# SAM9X75D1GN2 device description
Architecture: ARM926EJ-S; Family: SAM9; Series: SAM9X7
Registers are 32-bit, read-write, reset 0x0 unless marked. A register's access mark holds for its fields unless they carry their own. Offsets are from the block's base; [hi:lo] are bit positions; lines under a group give offsets from that group; {n}, {i} and the like mark numbered series; 'fields as' and 'values as' point back to an identical list.

## PWM — Pulse Width Modulation Controller
Instances: PWM 0xF8034000
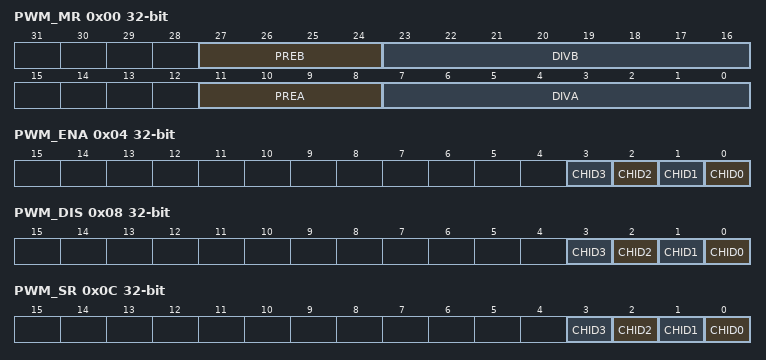
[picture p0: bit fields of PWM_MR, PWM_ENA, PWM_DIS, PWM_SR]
0x00 PWM_MR — PWM Mode Register
  [27:24] PREB — CLKB Source Clock Selection
    0=MCK (Peripheral clock); 1=MCKDIV2 (Peripheral clock divided by 2); 2=MCKDIV4 (Peripheral clock divided by 4); 3=MCKDIV8 (Peripheral clock divided by 8); 4=MCKDIV16 (Peripheral clock divided by 16); 5=MCKDIV32 (Peripheral clock divided by 32); 6=MCKDIV64 (Peripheral clock divided by 64); 7=MCKDIV128 (Peripheral clock divided by 128); 8=MCKDIV256 (Peripheral clock divided by 256); 9=MCKDIV512 (Peripheral clock divided by 512); 10=MCKDIV1024 (Peripheral clock divided by 1024)
  [23:16] DIVB — CLKB Divide Factor
    0=CLK_OFF (The CLKB internal source clock is turned off. The PWMx output is stuck when PWM_CMRx.CPRE=CLKB.); 1=CLK_DIV1 (CLKB is the clock selected by PREB.)
  [11:8] PREA — CLKA Source Clock Selection
    values as PREB
  [7:0] DIVA — CLKA Divide Factor
    0=CLK_OFF (The CLKA internal source clock is turned off. The PWMx output is stuck when PWM_CMRx.CPRE=CLKA.); 1=CLK_DIV1 (CLKA is the clock selected by PREA.)
0x04 PWM_ENA wo reset not defined — PWM Enable Register
  [all] fields
    0=No effect; 1=Enable PWM output for channel x
  [n] CHID{n} (n=0..3) — Channel ID
0x08 PWM_DIS wo reset not defined (atomic clear of PWM_SR) — PWM Disable Register
  [all] fields
    0=No effect; 1=Disable PWM output for channel x
  [n] CHID{n} (n=0..3) — Channel ID
0x0C PWM_SR ro — PWM Status Register
  [all] fields
    0=PWM output for channel x is disabled; 1=PWM output for channel x is enabled
  [n] CHID{n} (n=0..3) — Channel ID
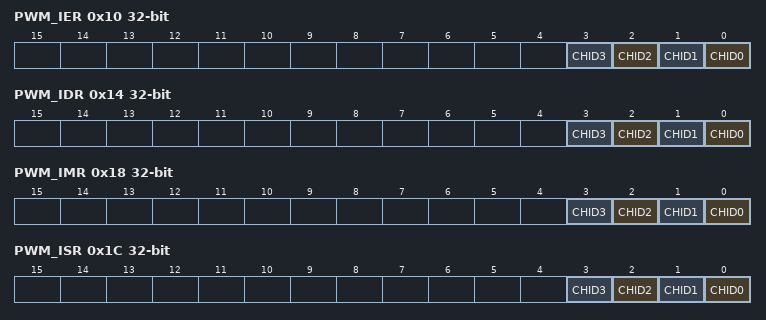
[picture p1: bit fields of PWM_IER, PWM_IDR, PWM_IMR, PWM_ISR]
0x10 PWM_IER wo reset not defined (atomic set of PWM_IMR) — PWM Interrupt Enable Register
  [all] fields
    0=No effect; 1=Enable interrupt for PWM channel x
  [n] CHID{n} (n=0..3) — Channel ID
0x14 PWM_IDR wo reset not defined (atomic clear of PWM_IMR) — PWM Interrupt Disable Register
  [all] fields
    0=No effect; 1=Disable interrupt for PWM channel x
  [n] CHID{n} (n=0..3) — Channel ID
0x18 PWM_IMR ro — PWM Interrupt Mask Register
  [all] fields
    0=Interrupt for PWM channel x is disabled; 1=Interrupt for PWM channel x is enabled
  [n] CHID{n} (n=0..3) — Channel ID
0x1C PWM_ISR ro — PWM Interrupt Status Register
  [all] fields
    0=No new channel period has been achieved since the last read of PWM_ISR; 1=At least one new channel period has been achieved since the last read of PWM_ISR
  [n] CHID{n} (n=0..3) — Channel ID
{0x200+0x20*i} PWM_CH_NUM[{i}] (i=0..3) group
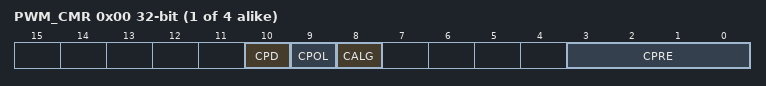
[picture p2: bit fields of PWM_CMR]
  0x00 PWM_CMR — PWM Channel Mode Register
    [10] CPD — Channel Update Period
      0=Writing to PWM_CUPDx will modify the duty cycle at the next period start event; 1=Writing to PWM_CUPDx will modify the period at the next period start event
    [9] CPOL — Channel Polarity
      0=LOW_POLARITY (The output waveform starts at a low level.); 1=HIGH_POLARITY (The output waveform starts at a high level.)
    [8] CALG — Channel Alignment
      0=LEFT_ALIGNED (The period is left-aligned.); 1=CENTER_ALIGNED (The period is center-aligned.)
    [3:0] CPRE — Channel Prescaler
      0=MCK (Peripheral clock); 1=MCKDIV2 (Peripheral clock divided by 2); 2=MCKDIV4 (Peripheral clock divided by 4); 3=MCKDIV8 (Peripheral clock divided by 8); 4=MCKDIV16 (Peripheral clock divided by 16); 5=MCKDIV32 (Peripheral clock divided by 32); 6=MCKDIV64 (Peripheral clock divided by 64); 7=MCKDIV128 (Peripheral clock divided by 128); 8=MCKDIV256 (Peripheral clock divided by 256); 9=MCKDIV512 (Peripheral clock divided by 512); 10=MCKDIV1024 (Peripheral clock divided by 1024); 11=CLKA (Clock A); 12=CLKB (Clock B)
  0x04 PWM_CDTY — PWM Channel Duty Cycle Register
    [31:0] CDTY — Channel Duty Cycle
  0x08 PWM_CPRD — PWM Channel Period Register
    [31:0] CPRD — Channel Period
  0x0C PWM_CCNT ro — PWM Channel Counter Register
    [31:0] CNT — Channel Counter Register
  0x10 PWM_CUPD wo reset not defined — PWM Channel Update Register
    [31:0] CUPD — Channel Update Register
